VERSION "vehicle 1"

NS_ :

BS_:

BU_: ECU Dash

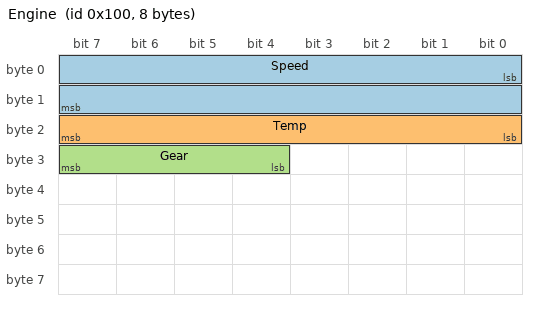
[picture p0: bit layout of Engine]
BO_ 256 Engine: 8 ECU
 SG_ Speed : 0|16@1+ (0.125,0) [0|8191.875] "rpm" Dash
 SG_ Temp : 16|8@1- (1,-40) [-40|87] "degC" Dash
 SG_ Gear : 31|4@0+ (1,0) [0|15] "" Dash

BO_ 2566844926 Status: 8 ECU
 SG_ Page M : 0|8@1+ (1,0) [0|255] "" Dash
 SG_ Volts m0 : 8|16@1+ (0.01,0) [0|655.35] "V" Dash
 SG_ Amps m1 : 8|16@1- (0.1,0) [-3276.8|3276.7] "A" Dash

BO_ 512 Wide: 12 ECU
 SG_ Counter : 0|32@1+ (1,0) [0|0] "" Dash

CM_ BO_ 256 "Engine data";
BA_DEF_ BO_ "GenMsgCycleTime" INT 0 65535;
BA_ "GenMsgCycleTime" BO_ 256 10;
BA_ "GenMsgCycleTime" BO_ 2566844926 50;
VAL_ 256 Gear 0 "Neutral" 1 "First" 2 "Second" ;
